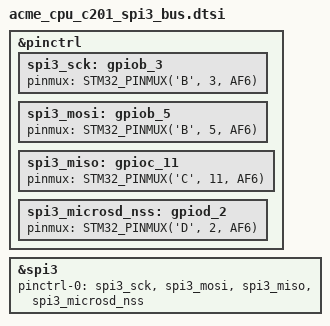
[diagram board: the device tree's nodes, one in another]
/*
 * Copyright (c) 2020 Volodymyr Sirous
 *
 * SPDX-License-Identifier: Apache-2.0
 */

&pinctrl {
  spi3_sck: gpiob_3 {
    /*pinmux = <STM32_PINMUX('B', 3, (STM32_PINMUX_ALT_FUNC_6 | STM32_PUSHPULL_NOPULL | STM32_OSPEEDR_VERY_HIGH_SPEED))>;*/
    pinmux = <STM32_PINMUX('B', 3, AF6)>;
  };

  spi3_mosi: gpiob_5 {
    /*pinmux = <STM32_PINMUX('B', 5, (STM32_PINMUX_ALT_FUNC_6 | STM32_PUSHPULL_NOPULL | STM32_OSPEEDR_VERY_HIGH_SPEED))>;*/
    pinmux = <STM32_PINMUX('B', 5, AF6)>;
  };

  spi3_miso: gpioc_11 {
    /*pinmux = <STM32_PINMUX('C', 11, (STM32_PINMUX_ALT_FUNC_6 | STM32_MODER_INPUT_MODE | STM32_PUPDR_PULL_UP))>;*/
    pinmux = <STM32_PINMUX('C', 11, AF6)>;
  };

  spi3_microsd_nss: gpiod_2 {
    /*pinmux = <STM32_PINMUX('D', 2, (STM32_PINMUX_FUNC_GPIO | STM32_PUSHPULL_PULLUP | STM32_OSPEEDR_VERY_HIGH_SPEED))>;*/
    pinmux = <STM32_PINMUX('D', 2, AF6)>;
  };
};

&spi3 {
    status = "okay";
    pinctrl-0 = <&spi3_sck &spi3_mosi &spi3_miso &spi3_microsd_nss>;

};
